VERSION ""

NS_ :

BS_:

BU_: LV_BOX

BO_ 1696 LV_BOX_ANALOG: 3 LV_BOX
 SG_ LVBOX_PWR : 0|12@1+ (0.0008058608058608059,0) [0|3.3] "V" Vector__XXX
 SG_ TSAL_PWR : 12|12@1+ (0.0008058608058608059,0) [0|3.3] "V" Vector__XXX

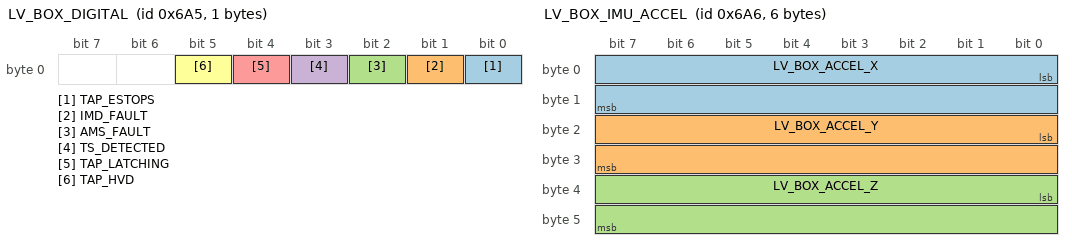
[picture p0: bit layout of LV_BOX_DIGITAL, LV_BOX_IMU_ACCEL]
BO_ 1701 LV_BOX_DIGITAL: 1 LV_BOX
 SG_ TAP_ESTOPS : 0|1@1+ (1,0) [0|1] "bool" Vector__XXX
 SG_ IMD_FAULT : 1|1@1+ (1,0) [0|1] "bool" Vector__XXX
 SG_ AMS_FAULT : 2|1@1+ (1,0) [0|1] "bool" Vector__XXX
 SG_ TS_DETECTED : 3|1@1+ (1,0) [0|1] "bool" Vector__XXX
 SG_ TAP_LATCHING : 4|1@1+ (1,0) [0|1] "bool" Vector__XXX
 SG_ TAP_HVD : 5|1@1+ (1,0) [0|1] "bool" Vector__XXX

BO_ 1702 LV_BOX_IMU_ACCEL: 6 LV_BOX
 SG_ LV_BOX_ACCEL_X : 0|16@1- (0.000122,0) [-4|4] "g" Vector__XXX
 SG_ LV_BOX_ACCEL_Y : 16|16@1- (0.000122,0) [-4|4] "g" Vector__XXX
 SG_ LV_BOX_ACCEL_Z : 32|16@1- (0.000122,0) [-4|4] "g" Vector__XXX

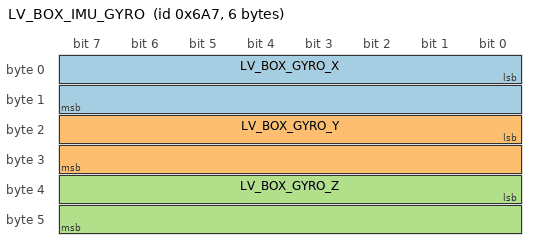
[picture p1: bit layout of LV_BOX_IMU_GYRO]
BO_ 1703 LV_BOX_IMU_GYRO: 6 LV_BOX
 SG_ LV_BOX_GYRO_X : 0|16@1- (0.0175,0) [-500|500] "dps" Vector__XXX
 SG_ LV_BOX_GYRO_Y : 16|16@1- (0.0175,0) [-500|500] "dps" Vector__XXX
 SG_ LV_BOX_GYRO_Z : 32|16@1- (0.0175,0) [-500|500] "dps" Vector__XXX

BO_ 1704 LV_BOX_TEMP: 4 LV_BOX
 SG_ LV_BOX_IMU_TEMP : 0|16@1- (0.00390625,25) [-40|85] "degC" Vector__XXX
 SG_ LV_BOX_AMBIENT_TEMP : 16|16@1- (0.0625,0) [-55|125] "degC" Vector__XXX

BO_ 1705 LV_BOX_STATUS: 1 LV_BOX
 SG_ LV_BOX_ISM330_OK : 0|1@1+ (1,0) [0|1] "" Vector__XXX
 SG_ LV_BOX_MCP9800_OK : 1|1@1+ (1,0) [0|1] "" Vector__XXX
